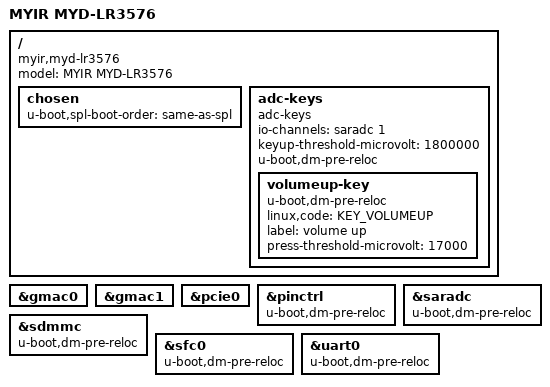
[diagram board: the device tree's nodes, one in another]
// SPDX-License-Identifier: (GPL-2.0+ OR MIT)
/*
 * Copyright (c) 2024 MYIR Electronics Co., Ltd.
 * Copyright (c) 2024 Rockchip Electronics Co., Ltd.
 */

/dts-v1/;
#include "rk3576.dtsi"
#include "rk3576-u-boot.dtsi"
#include <dt-bindings/input/input.h>

/ {
	model = "MYIR MYD-LR3576";
	compatible = "myir,myd-lr3576", "rockchip,rk3576";

	chosen {
		u-boot,spl-boot-order = &sdmmc, "same-as-spl";
	};

	adc-keys {
		compatible = "adc-keys";
		io-channels = <&saradc 1>;
		io-channel-names = "buttons";
		keyup-threshold-microvolt = <1800000>;
		u-boot,dm-pre-reloc;
		status = "okay";

		volumeup-key {
			u-boot,dm-pre-reloc;
			linux,code = <KEY_VOLUMEUP>;
			label = "volume up";
			press-threshold-microvolt = <17000>;
		};
	};
};

&gmac0 {
	status = "okay";
};

&gmac1 {
	status = "okay";
};

&pcie0 {
	status = "okay";
};

&pinctrl {
	u-boot,dm-pre-reloc;
};

&saradc {
	u-boot,dm-pre-reloc;
	status = "okay";
};

&sdmmc {
	u-boot,dm-pre-reloc;
	status = "okay";
};

&sfc0 {
	u-boot,dm-pre-reloc;
	status = "okay";
};

&uart0 {
	u-boot,dm-pre-reloc;
	status = "okay";
};
